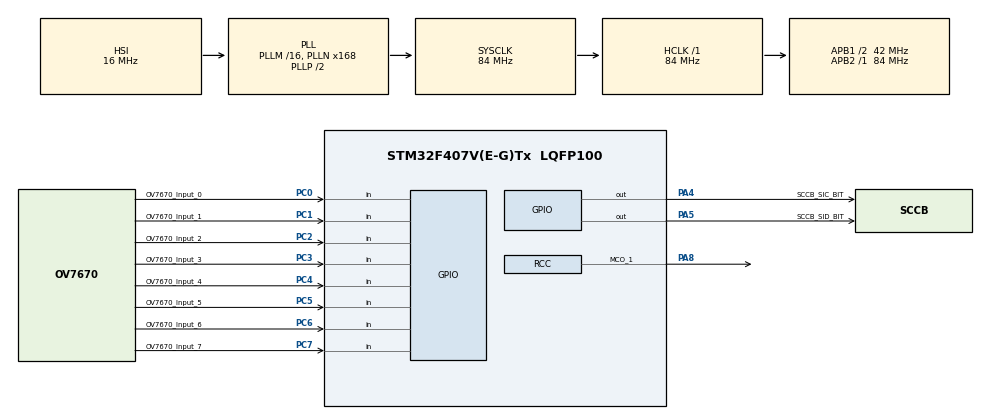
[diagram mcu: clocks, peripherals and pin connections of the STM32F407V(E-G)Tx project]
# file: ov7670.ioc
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Mcu.Family=STM32F4
Mcu.Name=STM32F407V(E-G)Tx
Mcu.Package=LQFP100
NVIC.PriorityGroup=NVIC_PRIORITYGROUP_4
PA4.GPIO_Label=SCCB_SIC_BIT
PA4.GPIO_Speed=GPIO_SPEED_FREQ_MEDIUM
PA4.Signal=GPIO_Output
PA5.GPIO_Label=SCCB_SID_BIT
PA5.GPIO_Speed=GPIO_SPEED_FREQ_MEDIUM
PA5.PinState=GPIO_PIN_RESET
PA5.Signal=GPIO_Output
PA8.GPIO_Speed=GPIO_SPEED_FREQ_MEDIUM
PA8.Mode=Clock-out-1
PA8.Signal=RCC_MCO_1
PC0.GPIO_Label=OV7670_Input_0
PC0.GPIO_PuPd=GPIO_PULLDOWN
PC0.Signal=GPIO_Input
PC1.GPIO_Label=OV7670_Input_1
PC1.GPIO_Mode=GPIO_MODE_INPUT
PC1.GPIO_PuPd=GPIO_PULLDOWN
PC1.Signal=GPIO_Input
PC2.GPIO_Label=OV7670_Input_2
PC2.GPIO_Mode=GPIO_MODE_INPUT
PC2.GPIO_PuPd=GPIO_PULLDOWN
PC2.Signal=GPIO_Input
PC3.GPIO_Label=OV7670_Input_3
PC3.GPIO_Mode=GPIO_MODE_INPUT
PC3.GPIO_PuPd=GPIO_PULLDOWN
PC3.Signal=GPIO_Input
PC4.GPIO_Label=OV7670_Input_4
PC4.GPIO_Mode=GPIO_MODE_INPUT
PC4.GPIO_PuPd=GPIO_PULLDOWN
PC4.Signal=GPIO_Input
PC5.GPIO_Label=OV7670_Input_5
PC5.GPIO_Mode=GPIO_MODE_INPUT
PC5.GPIO_PuPd=GPIO_PULLDOWN
PC5.Signal=GPIO_Input
PC6.GPIO_Label=OV7670_Input_6
PC6.GPIO_Mode=GPIO_MODE_INPUT
PC6.GPIO_PuPd=GPIO_PULLDOWN
PC6.Signal=GPIO_Input
PC7.GPIO_Label=OV7670_Input_7
PC7.GPIO_Mode=GPIO_MODE_INPUT
PC7.GPIO_PuPd=GPIO_PULLDOWN
PC7.Signal=GPIO_Input
ProjectManager.HeapSize=0x200
ProjectManager.StackSize=0x400
ProjectManager.TargetToolchain=STM32CubeIDE
RCC.48MHZClocksFreq_Value=42000000
RCC.AHBFreq_Value=84000000
RCC.APB1CLKDivider=RCC_HCLK_DIV2
RCC.APB1Freq_Value=42000000
RCC.APB1TimFreq_Value=84000000
RCC.APB2Freq_Value=84000000
RCC.APB2TimFreq_Value=84000000
RCC.CortexFreq_Value=84000000
RCC.HCLKFreq_Value=84000000
RCC.HSE_VALUE=25000000
RCC.HSI_VALUE=16000000
RCC.LSE_VALUE=32768
RCC.PLLN=168
RCC.SYSCLKFreq_VALUE=84000000
RCC.SYSCLKSource=RCC_SYSCLKSOURCE_PLLCLK
RCC.VCOOutputFreq_Value=168000000
board=custom

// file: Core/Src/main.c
/* USER CODE BEGIN Header */
/**
  ******************************************************************************
  * @file           : main.c
  * @brief          : Main program body
  ******************************************************************************
  * @attention
  *
  * <h2><center>&copy; Copyright (c) 2020 STMicroelectronics.
  * All rights reserved.</center></h2>
  *
  * This software component is licensed by ST under BSD 3-Clause license,
  * the "License"; You may not use this file except in compliance with the
  * License. You may obtain a copy of the License at:
  *                        opensource.org/licenses/BSD-3-Clause
  *
  ******************************************************************************
  */
/* USER CODE END Header */

#include "main.h"

void SystemClock_Config(void);
static void MX_GPIO_Init(void);

int main(void)
{
  /* USER CODE BEGIN 1 */
  uint16_t value();
  /* USER CODE END 1 */

  /* MCU Configuration--------------------------------------------------------*/

  /* Reset of all peripherals, Initializes the Flash interface and the Systick. */
  HAL_Init();

  /* Configure the system clock */
  SystemClock_Config();

  /* Initialize all configured peripherals */
  MX_GPIO_Init();
  /* USER CODE BEGIN 2 */
  OV7670_CLK_Init();
  OV7670_GPIO_Init();
  /* USER CODE END 2 */

  /* Infinite loop */
  while (1)
  {

  }
}

void SystemClock_Config(void)
{
  RCC_OscInitTypeDef RCC_OscInitStruct = {0};
  RCC_ClkInitTypeDef RCC_ClkInitStruct = {0};

  /** Configure the main internal regulator output voltage
  */
  __HAL_RCC_PWR_CLK_ENABLE();
  __HAL_PWR_VOLTAGESCALING_CONFIG(PWR_REGULATOR_VOLTAGE_SCALE1);
  /** Initializes the CPU, AHB and APB busses clocks
  */
  RCC_OscInitStruct.OscillatorType = RCC_OSCILLATORTYPE_HSI;
  RCC_OscInitStruct.HSIState = RCC_HSI_ON;
  RCC_OscInitStruct.HSICalibrationValue = RCC_HSICALIBRATION_DEFAULT;
  RCC_OscInitStruct.PLL.PLLState = RCC_PLL_ON;
  RCC_OscInitStruct.PLL.PLLSource = RCC_PLLSOURCE_HSI;
  RCC_OscInitStruct.PLL.PLLM = 16;
  RCC_OscInitStruct.PLL.PLLN = 168;
  RCC_OscInitStruct.PLL.PLLP = RCC_PLLP_DIV2;
  RCC_OscInitStruct.PLL.PLLQ = 4;
  if (HAL_RCC_OscConfig(&RCC_OscInitStruct) != HAL_OK)
  {
    Error_Handler();
  }
  /** Initializes the CPU, AHB and APB busses clocks
  */
  RCC_ClkInitStruct.ClockType = RCC_CLOCKTYPE_HCLK | RCC_CLOCKTYPE_SYSCLK | RCC_CLOCKTYPE_PCLK1 | RCC_CLOCKTYPE_PCLK2;
  RCC_ClkInitStruct.SYSCLKSource = RCC_SYSCLKSOURCE_PLLCLK;
  RCC_ClkInitStruct.AHBCLKDivider = RCC_SYSCLK_DIV1;
  RCC_ClkInitStruct.APB1CLKDivider = RCC_HCLK_DIV2;
  RCC_ClkInitStruct.APB2CLKDivider = RCC_HCLK_DIV1;

  if (HAL_RCC_ClockConfig(&RCC_ClkInitStruct, FLASH_LATENCY_2) != HAL_OK)
  {
    Error_Handler();
  }
  HAL_RCC_MCOConfig(RCC_MCO1, RCC_MCO1SOURCE_HSI, RCC_MCODIV_1);
}

static void MX_GPIO_Init(void)
{
  GPIO_InitTypeDef GPIO_InitStruct = {0};

  /* GPIO Ports Clock Enable */
  __HAL_RCC_GPIOC_CLK_ENABLE();
  __HAL_RCC_GPIOA_CLK_ENABLE();

  /*Configure GPIO pin Output Level */
  HAL_GPIO_WritePin(GPIOA, SCCB_SIC_BIT_Pin | SCCB_SID_BIT_Pin, GPIO_PIN_RESET);

  /*Configure GPIO pins : OV7670_Input_0_Pin OV7670_Input_1_Pin OV7670_Input_2_Pin OV7670_Input_3_Pin
                           OV7670_Input_4_Pin OV7670_Input_5_Pin OV7670_Input_6_Pin OV7670_Input_7_Pin */
  GPIO_InitStruct.Pin = OV7670_Input_0_Pin | OV7670_Input_1_Pin | OV7670_Input_2_Pin | OV7670_Input_3_Pin | OV7670_Input_4_Pin | OV7670_Input_5_Pin | OV7670_Input_6_Pin | OV7670_Input_7_Pin;
  GPIO_InitStruct.Mode = GPIO_MODE_INPUT;
  GPIO_InitStruct.Pull = GPIO_PULLDOWN;
  HAL_GPIO_Init(GPIOC, &GPIO_InitStruct);

  /*Configure GPIO pins : SCCB_SIC_BIT_Pin SCCB_SID_BIT_Pin */
  GPIO_InitStruct.Pin = SCCB_SIC_BIT_Pin | SCCB_SID_BIT_Pin;
  GPIO_InitStruct.Mode = GPIO_MODE_OUTPUT_PP;
  GPIO_InitStruct.Pull = GPIO_NOPULL;
  GPIO_InitStruct.Speed = GPIO_SPEED_FREQ_MEDIUM;
  HAL_GPIO_Init(GPIOA, &GPIO_InitStruct);

  /*Configure GPIO pin : PA8 */
  GPIO_InitStruct.Pin = GPIO_PIN_8;
  GPIO_InitStruct.Mode = GPIO_MODE_AF_PP;
  GPIO_InitStruct.Pull = GPIO_NOPULL;
  GPIO_InitStruct.Speed = GPIO_SPEED_FREQ_MEDIUM;
  GPIO_InitStruct.Alternate = GPIO_AF0_MCO;
  HAL_GPIO_Init(GPIOA, &GPIO_InitStruct);
}

void Error_Handler(void)
{
}

/************************ (C) COPYRIGHT STMicroelectronics *****END OF FILE****/
